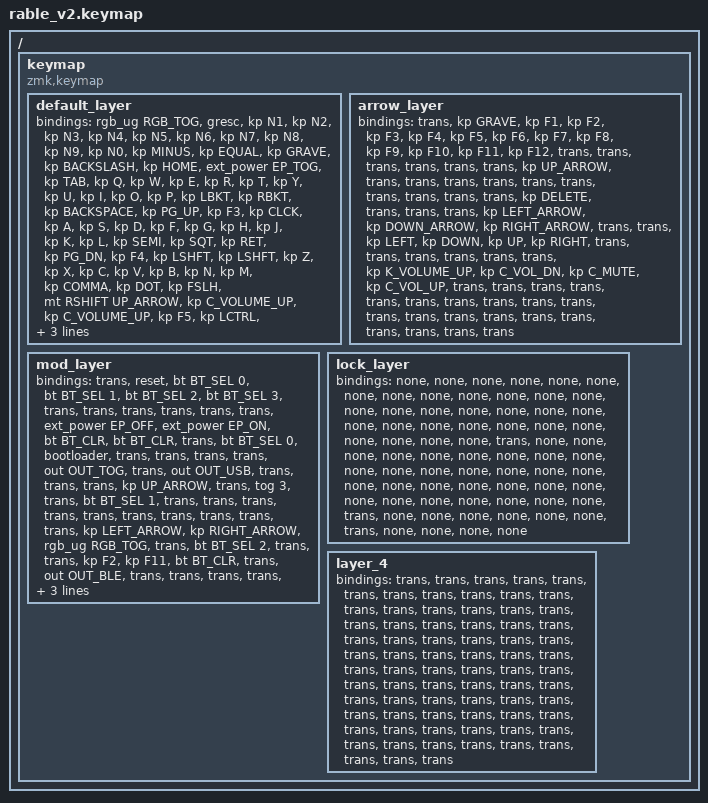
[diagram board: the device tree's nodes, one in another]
/*
 * Copyright (c) 2021 Nick Winans
 *
 * SPDX-License-Identifier: MIT
 */

#include <behaviors.dtsi>
#include <dt-bindings/zmk/bt.h>
#include <dt-bindings/zmk/ext_power.h>
#include <dt-bindings/zmk/keys.h>
#include <dt-bindings/zmk/outputs.h>
#include <dt-bindings/zmk/rgb.h>

/ {
    keymap {
        compatible = "zmk,keymap";

        default_layer {
            bindings = <
&rgb_ug RGB_TOG  &gresc  &kp N1  &kp N2  &kp N3  &kp N4  &kp N5  &kp N6  &kp N7  &kp N8  &kp N9  &kp N0  &kp MINUS  &kp EQUAL  &kp GRAVE  &kp BACKSLASH  &kp HOME  &ext_power EP_TOG  &kp TAB  &kp Q  &kp W  &kp E  &kp R  &kp T  &kp Y  &kp U  &kp I  &kp O  &kp P  &kp LBKT  &kp RBKT  &kp BACKSPACE  &kp PG_UP  &kp F3  &kp CLCK  &kp A  &kp S  &kp D  &kp F  &kp G  &kp H  &kp J  &kp K  &kp L  &kp SEMI  &kp SQT  &kp RET  &kp PG_DN  &kp F4  &kp LSHFT  &kp LSHFT  &kp Z  &kp X  &kp C  &kp V  &kp B  &kp N  &kp M  &kp COMMA  &kp DOT  &kp FSLH  &mt RSHIFT UP_ARROW  &kp C_VOLUME_UP  &kp C_VOLUME_UP  &kp F5  &kp LCTRL  &kp LEFT_WIN  &kp LALT  &kp SPACE  &tog 1  &tog 1  &kp PRINTSCREEN  &kp C_VOLUME_DOWN  &kp RIGHT
            >;
        };

        arrow_layer {
            bindings = <
&trans  &kp GRAVE  &kp F1  &kp F2  &kp F3  &kp F4  &kp F5  &kp F6  &kp F7  &kp F8  &kp F9  &kp F10  &kp F11  &kp F12  &trans  &trans  &trans  &trans  &trans  &trans  &kp UP_ARROW  &trans  &trans  &trans  &trans  &trans  &trans  &trans  &trans  &trans  &trans  &kp DELETE  &trans  &trans  &trans  &kp LEFT_ARROW  &kp DOWN_ARROW  &kp RIGHT_ARROW  &trans  &trans  &kp LEFT  &kp DOWN  &kp UP  &kp RIGHT  &trans  &trans  &trans  &trans  &trans  &trans  &kp K_VOLUME_UP  &kp C_VOL_DN  &kp C_MUTE  &kp C_VOL_UP  &trans  &trans  &trans  &trans  &trans  &trans  &trans  &trans  &trans  &trans  &trans  &trans  &trans  &trans  &trans  &trans  &trans  &trans  &trans  &trans
            >;
        };

        mod_layer {
            bindings = <
&trans  &reset  &bt BT_SEL 0  &bt BT_SEL 1  &bt BT_SEL 2  &bt BT_SEL 3  &trans  &trans  &trans  &trans  &trans  &trans  &ext_power EP_OFF  &ext_power EP_ON  &bt BT_CLR  &bt BT_CLR  &trans  &bt BT_SEL 0  &bootloader  &trans  &trans  &trans  &trans  &out OUT_TOG  &trans  &out OUT_USB  &trans  &trans  &trans  &kp UP_ARROW  &trans  &tog 3  &trans  &bt BT_SEL 1  &trans  &trans  &trans  &trans  &trans  &trans  &trans  &trans  &trans  &trans  &kp LEFT_ARROW  &kp RIGHT_ARROW  &rgb_ug RGB_TOG  &trans  &bt BT_SEL 2  &trans  &trans  &kp F2  &kp F11  &bt BT_CLR  &trans  &out OUT_BLE  &trans  &trans  &trans  &trans  &kp DOWN_ARROW  &trans  &trans  &trans  &bt BT_SEL 3  &trans  &trans  &trans  &trans  &trans  &trans  &trans  &trans  &trans
            >;
        };

        lock_layer {
            bindings = <
&none  &none  &none  &none  &none  &none  &none  &none  &none  &none  &none  &none  &none  &none  &none  &none  &none  &none  &none  &none  &none  &none  &none  &none  &none  &none  &none  &none  &none  &none  &none  &trans  &none  &none  &none  &none  &none  &none  &none  &none  &none  &none  &none  &none  &none  &none  &none  &none  &none  &none  &none  &none  &none  &none  &none  &none  &none  &none  &none  &none  &none  &none  &trans  &none  &none  &none  &none  &none  &none  &trans  &none  &none  &none  &none
            >;
        };

        layer_4 {
            bindings = <
&trans  &trans  &trans  &trans  &trans  &trans  &trans  &trans  &trans  &trans  &trans  &trans  &trans  &trans  &trans  &trans  &trans  &trans  &trans  &trans  &trans  &trans  &trans  &trans  &trans  &trans  &trans  &trans  &trans  &trans  &trans  &trans  &trans  &trans  &trans  &trans  &trans  &trans  &trans  &trans  &trans  &trans  &trans  &trans  &trans  &trans  &trans  &trans  &trans  &trans  &trans  &trans  &trans  &trans  &trans  &trans  &trans  &trans  &trans  &trans  &trans  &trans  &trans  &trans  &trans  &trans  &trans  &trans  &trans  &trans  &trans  &trans  &trans  &trans
            >;
        };
    };
};
